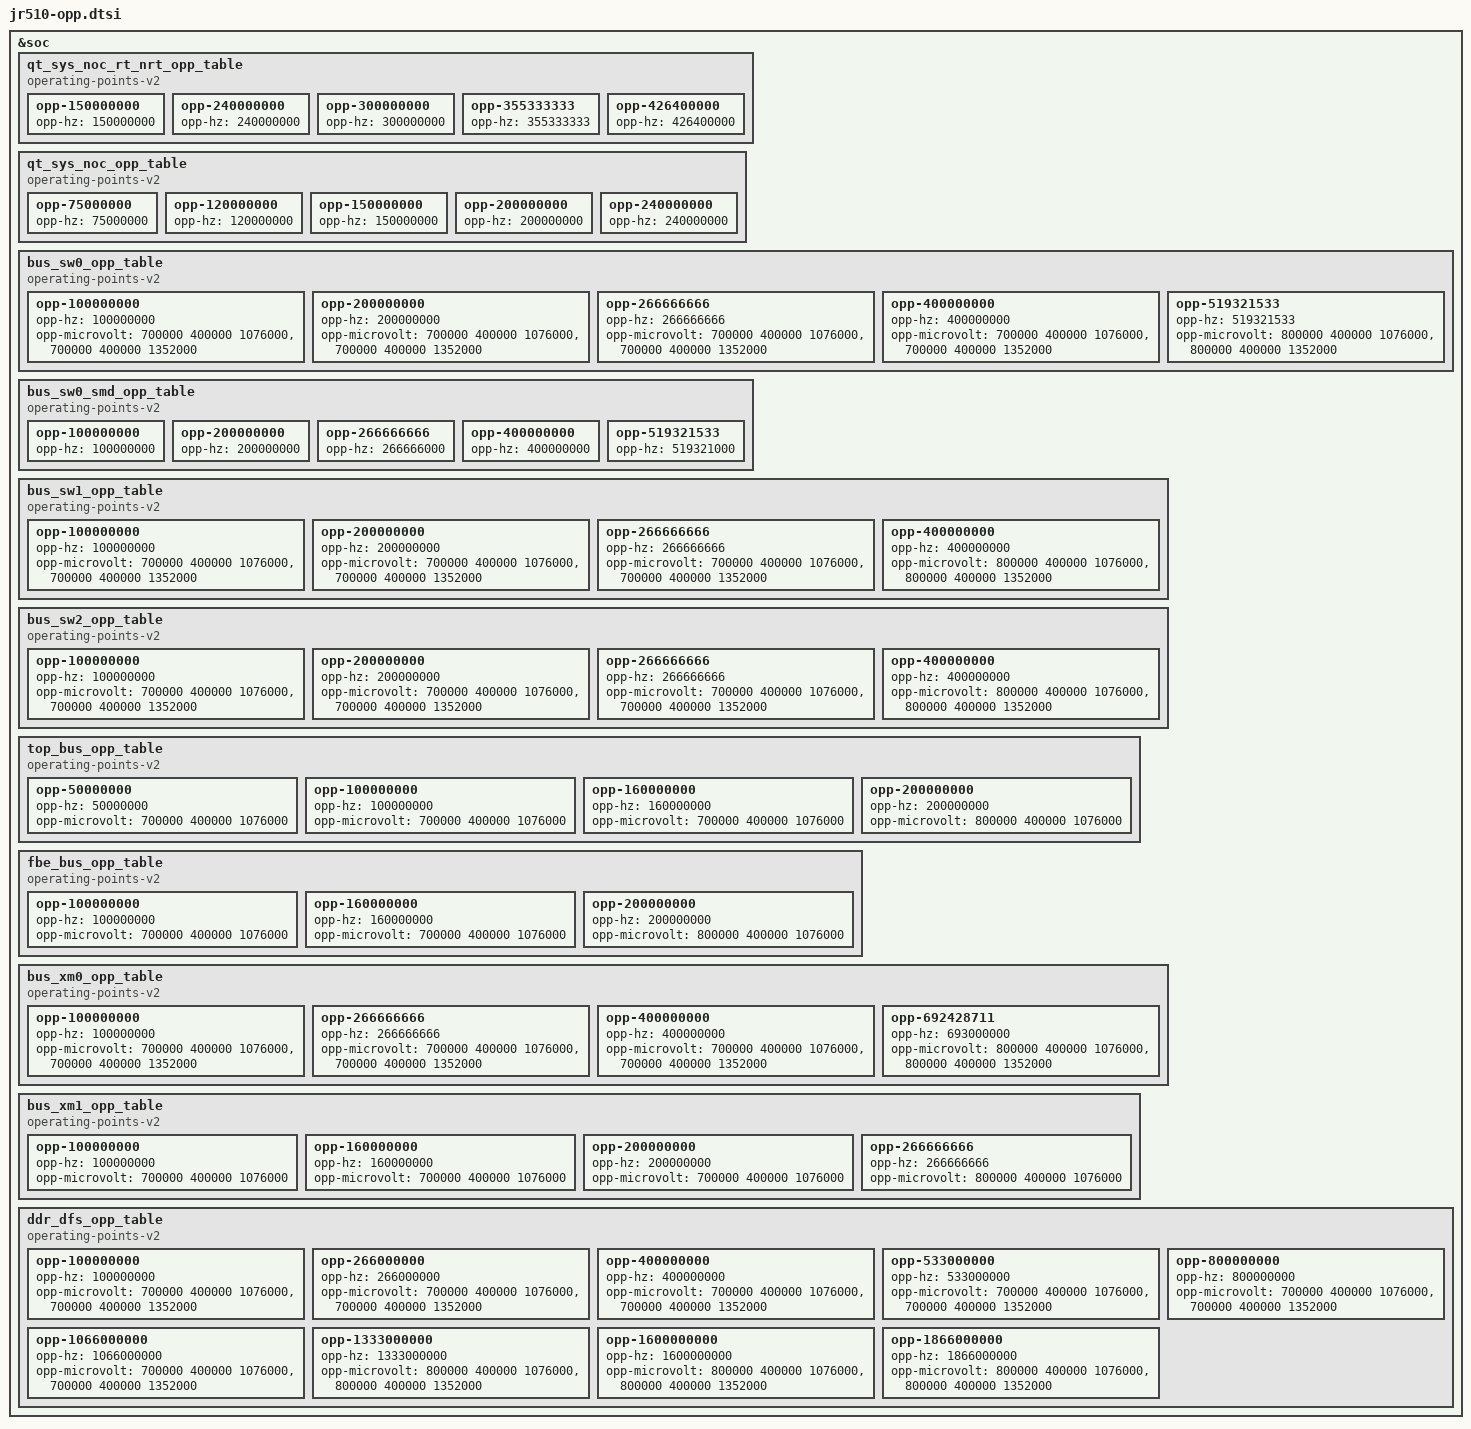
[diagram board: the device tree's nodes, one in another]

&soc {
	qt_sys_noc_rt_nrt_opp_table: qt_sys_noc_rt_nrt_opp_table {
		compatible = "operating-points-v2";

		opp-150000000 {
			opp-hz = /bits/ 64 <150000000>;
		};
		opp-240000000 {
			opp-hz = /bits/ 64 <240000000>;
		};
		opp-300000000 {
			opp-hz = /bits/ 64 <300000000>;
		};
		opp-355333333 {
			opp-hz = /bits/ 64 <355333333>;
		};
		opp-426400000 {
			opp-hz = /bits/ 64 <426400000>;
		};
	};

	qt_sys_noc_opp_table: qt_sys_noc_opp_table {
		compatible = "operating-points-v2";

		opp-75000000 {
			opp-hz = /bits/ 64 <75000000>;
		};
		opp-120000000 {
			opp-hz = /bits/ 64 <120000000>;
		};
		opp-150000000 {
			opp-hz = /bits/ 64 <150000000>;
		};
		opp-200000000 {
			opp-hz = /bits/ 64 <200000000>;
		};
		opp-240000000 {
			opp-hz = /bits/ 64 <240000000>;
		};
	};

	bus_sw0_opp_table: bus_sw0_opp_table {
		compatible = "operating-points-v2";

		opp-100000000 {
			opp-hz = /bits/ 64 <100000000>;
			opp-microvolt = <700000 400000 1076000>,
					<700000 400000 1352000>;
		};
		opp-200000000 {
			opp-hz = /bits/ 64 <200000000>;
			opp-microvolt = <700000 400000 1076000>,
					<700000 400000 1352000>;
		};
		opp-266666666 {
			opp-hz = /bits/ 64 <266666666>;
			opp-microvolt = <700000 400000 1076000>,
					<700000 400000 1352000>;
		};
		opp-400000000 {
			opp-hz = /bits/ 64 <400000000>;
			opp-microvolt = <700000 400000 1076000>,
					<700000 400000 1352000>;
		};
		opp-519321533 {
			opp-hz = /bits/ 64 <519321533>;
			opp-microvolt = <800000 400000 1076000>,
					<800000 400000 1352000>;
		};
	};

	bus_sw0_smd_opp_table: bus_sw0_smd_opp_table {
		compatible = "operating-points-v2";

		opp-100000000 {
			opp-hz = /bits/ 64 <100000000>;
		};
		opp-200000000 {
			opp-hz = /bits/ 64 <200000000>;
		};
		opp-266666666 {
			opp-hz = /bits/ 64 <266666000>;
		};
		opp-400000000 {
			opp-hz = /bits/ 64 <400000000>;
		};
		opp-519321533 {
			opp-hz = /bits/ 64 <519321000>;
		};
	};

	bus_sw1_opp_table: bus_sw1_opp_table {
		compatible = "operating-points-v2";

		opp-100000000 {
			opp-hz = /bits/ 64 <100000000>;
			opp-microvolt = <700000 400000 1076000>,
					<700000 400000 1352000>;
		};
		opp-200000000 {
			opp-hz = /bits/ 64 <200000000>;
			opp-microvolt = <700000 400000 1076000>,
					<700000 400000 1352000>;
		};
		opp-266666666 {
			opp-hz = /bits/ 64 <266666666>;
			opp-microvolt = <700000 400000 1076000>,
					<700000 400000 1352000>;
		};
		opp-400000000 {
			opp-hz = /bits/ 64 <400000000>;
			opp-microvolt = <800000 400000 1076000>,
					<800000 400000 1352000>;
		};
	};

	bus_sw2_opp_table: bus_sw2_opp_table {
		compatible = "operating-points-v2";

		opp-100000000 {
			opp-hz = /bits/ 64 <100000000>;
			opp-microvolt = <700000 400000 1076000>,
					<700000 400000 1352000>;
		};
		opp-200000000 {
			opp-hz = /bits/ 64 <200000000>;
			opp-microvolt = <700000 400000 1076000>,
					<700000 400000 1352000>;
		};
		opp-266666666 {
			opp-hz = /bits/ 64 <266666666>;
			opp-microvolt = <700000 400000 1076000>,
					<700000 400000 1352000>;
		};
		opp-400000000 {
			opp-hz = /bits/ 64 <400000000>;
			opp-microvolt = <800000 400000 1076000>,
					<800000 400000 1352000>;
		};
	};

	top_bus_opp_table: top_bus_opp_table {
		compatible = "operating-points-v2";

		opp-50000000 {
			opp-hz = /bits/ 64 <50000000>;
			opp-microvolt = <700000 400000 1076000>;
		};
		opp-100000000 {
			opp-hz = /bits/ 64 <100000000>;
			opp-microvolt = <700000 400000 1076000>;
		};
		opp-160000000 {
			opp-hz = /bits/ 64 <160000000>;
			opp-microvolt = <700000 400000 1076000>;
		};
		opp-200000000 {
			opp-hz = /bits/ 64 <200000000>;
			opp-microvolt = <800000 400000 1076000>;
		};
	};

	fbe_bus_opp_table: fbe_bus_opp_table {
		compatible = "operating-points-v2";

		opp-100000000 {
			opp-hz = /bits/ 64 <100000000>;
			opp-microvolt = <700000 400000 1076000>;
		};
		opp-160000000 {
			opp-hz = /bits/ 64 <160000000>;
			opp-microvolt = <700000 400000 1076000>;
		};
		opp-200000000 {
			opp-hz = /bits/ 64 <200000000>;
			opp-microvolt = <800000 400000 1076000>;
		};
	};

	bus_xm0_opp_table: bus_xm0_opp_table {
		compatible = "operating-points-v2";

		opp-100000000 {
			opp-hz = /bits/ 64 <100000000>;
			opp-microvolt = <700000 400000 1076000>,
					<700000 400000 1352000>;
		};
		opp-266666666 {
			opp-hz = /bits/ 64 <266666666>;
			opp-microvolt = <700000 400000 1076000>,
					<700000 400000 1352000>;
		};

		opp-400000000 {
			opp-hz = /bits/ 64 <400000000>;
			opp-microvolt = <700000 400000 1076000>,
					<700000 400000 1352000>;
		};
		opp-692428711 {
			opp-hz = /bits/ 64 <693000000>;
			opp-microvolt = <800000 400000 1076000>,
					<800000 400000 1352000>;
		};
	};

	bus_xm1_opp_table: bus_xm1_opp_table {
		compatible = "operating-points-v2";

		opp-100000000 {
			opp-hz = /bits/ 64 <100000000>;
			opp-microvolt = <700000 400000 1076000>;
		};
		opp-160000000 {
			opp-hz = /bits/ 64 <160000000>;
			opp-microvolt = <700000 400000 1076000>;
		};
		opp-200000000 {
			opp-hz = /bits/ 64 <200000000>;
			opp-microvolt = <700000 400000 1076000>;
		};
		opp-266666666 {
			opp-hz = /bits/ 64 <266666666>;
			opp-microvolt = <800000 400000 1076000>;
		};
	};

	ddr_dfs_opp_table: ddr_dfs_opp_table {
		compatible = "operating-points-v2";

		opp-100000000 {
			opp-hz = /bits/ 64 <100000000>;
			opp-microvolt = <700000 400000 1076000>,
					<700000 400000 1352000>;
		};
		opp-266000000 {
			opp-hz = /bits/ 64 <266000000>;
			opp-microvolt = <700000 400000 1076000>,
					<700000 400000 1352000>;
		};
		opp-400000000 {
			opp-hz = /bits/ 64 <400000000>;
			opp-microvolt = <700000 400000 1076000>,
					<700000 400000 1352000>;
		};
		opp-533000000 {
			opp-hz = /bits/ 64 <533000000>;
			opp-microvolt = <700000 400000 1076000>,
					<700000 400000 1352000>;
		};
		opp-800000000 {
			opp-hz = /bits/ 64 <800000000>;
			opp-microvolt = <700000 400000 1076000>,
					<700000 400000 1352000>;
		};
		opp-1066000000 {
			opp-hz = /bits/ 64 <1066000000>;
			opp-microvolt = <700000 400000 1076000>,
					<700000 400000 1352000>;
		};
		opp-1333000000 {
			opp-hz = /bits/ 64 <1333000000>;
			opp-microvolt = <800000 400000 1076000>,
					<800000 400000 1352000>;
		};
		opp-1600000000 {
			opp-hz = /bits/ 64 <1600000000>;
			opp-microvolt = <800000 400000 1076000>,
					<800000 400000 1352000>;
		};
		opp-1866000000 {
			opp-hz = /bits/ 64 <1866000000>;
			opp-microvolt = <800000 400000 1076000>,
					<800000 400000 1352000>;
		};
	};
};
